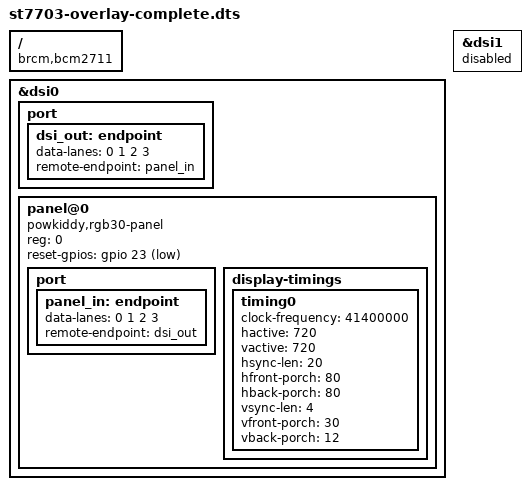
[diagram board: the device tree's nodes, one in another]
/dts-v1/;
/plugin/;

/ {
    compatible = "brcm,bcm2711";
};

&dsi0 {
    status = "okay";
    #address-cells = <1>;
    #size-cells = <0>;

    port {
        dsi_out: endpoint {
            data-lanes = <0 1 2 3>;
            remote-endpoint = <&panel_in>;
        };
    };

    panel@0 {
        compatible = "powkiddy,rgb30-panel", "sitronix,st7703";
        reg = <0>;
        reset-gpios = <&gpio 23 1>;

        port {
            panel_in: endpoint {
                data-lanes = <0 1 2 3>;
                remote-endpoint = <&dsi_out>;
            };
        };

        display-timings {
            timing0 {
                clock-frequency = <41400000>;
                hactive = <720>;
                vactive = <720>;
                hsync-len = <20>;
                hfront-porch = <80>;
                hback-porch = <80>;
                vsync-len = <4>;
                vfront-porch = <30>;
                vback-porch = <12>;
            };
        };
    };
};

&dsi1 {
    status = "disabled";
};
